# pse84 register map
Vendor: Infineon Technologies; Series: PSE84; File version: 1.0
CPU: CM33 r0p1, little endian, MPU, FPU, VTOR, 3 interrupt priority bits
Registers are 32-bit, read-write, reset 0x0 unless marked. A register's access mark holds for its fields unless they carry their own. Offsets are from the block's base; [hi:lo] are bit positions; lines under a group give offsets from that group; {n}, {i} and the like mark numbered series; <NAME> marks a mode.

## SMIF0 (part 1 of 3) — SMIF subsystem (1 SMIF cores, no bridge, 1 cache_block and 1 Q_LPI expander)
Base 0x44440000
Same registers: SMIF1 0x44480000
0x10000 CACHE_BLOCK group — Serial Memory Interface
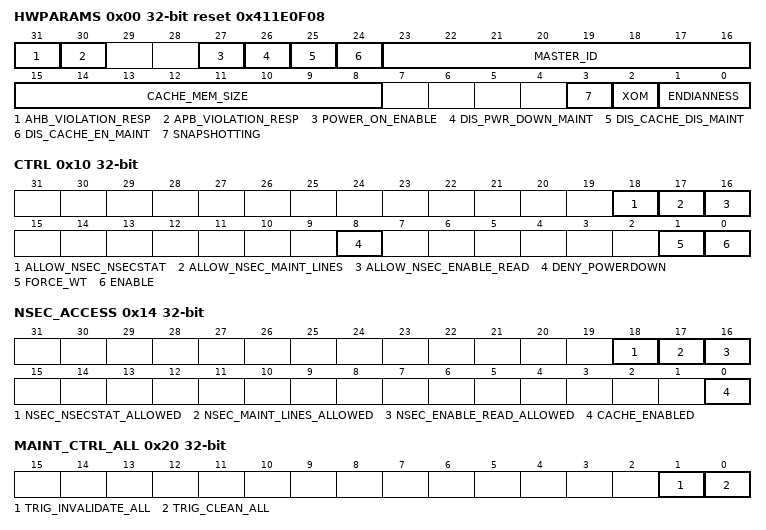
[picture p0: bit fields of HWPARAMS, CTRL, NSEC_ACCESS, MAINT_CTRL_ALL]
  0x00 HWPARAMS ro reset 0x411E0F08 — Hardware Parameter register
    [31] AHB_VIOLATION_RESP — Respond with error (1) or RAZ/WI (0) for illegal AHB operations (eg. XOM). Fixed to 0 if XOM render parameter is OFF
    [30] APB_VIOLATION_RESP — Respond with error (1) or RAZ/WI (0) for illegal APB operations. These are transfers that are any of: non-privileged, instruction, unaligned or incomplete write strobes
    [27] POWER_ON_ENABLE — Value of the input configuration port that controls whether the cache should be enabled automatically after power up
    [26] DIS_PWR_DOWN_MAINT — Value of the input configuration port that controls the function to disable automatic clean at power down
    [25] DIS_CACHE_DIS_MAINT — Value of the input configuration port that controls the function to disable automatic maintenance at disabling the cache
    [24] DIS_CACHE_EN_MAINT — Value of the input configuration port that controls the function to disable automatic maintenance at enabling the cache
    [23:16] MASTER_ID — The cache generates transactions with this ID
    [15:8] CACHE_MEM_SIZE — Cache memory size in address bits. The actual size is this value to the power of 2 (11->2KB,..,16->64KB)
    [3] SNAPSHOTTING — SNAPSHOTTING supported 1-ON, 0-OFF
    [2] XOM — XOM supported 1-ON, 0-OFF
    [1:0] ENDIANNESS — The endianness of the module 0 - LE, 1 - BE8, 2 - BE32
  0x10 CTRL — Control Register
    [18] ALLOW_NSEC_NSECSTAT — Allow non-secure to read and control non-secure statistics counter registers and receive saturation interrupt
    [17] ALLOW_NSEC_MAINT_LINES — Allow non-secure to trigger maintenance (only for lines and only non-secure views of cache lines)
    [16] ALLOW_NSEC_ENABLE_READ — Allow non-secure to see if the cache is enabled
    [8] DENY_POWERDOWN — When set, power-down LPI requests are denied. Does not affect clock LPI requests.
    [1] FORCE_WT — Force Write-Through policy
    [0] ENABLE — Enable cache (1-enabled, 0-disabled)
  0x14 NSEC_ACCESS ro — Non-secure access information
    [18] NSEC_NSECSTAT_ALLOWED — Non-secure is allowed to read and control non-secure statistics counters and receives saturation interrupt
    [17] NSEC_MAINT_LINES_ALLOWED — Non-secure is allowed to trigger maintenance (only for lines)
    [16] NSEC_ENABLE_READ_ALLOWED — Non-secure is allowed to see the cache enabled state
    [0] CACHE_ENABLED — Enable cache (1-enabled, 0-disabled). Only valid if bit NSEC_ENABLE_READ_ALLOWED is set
  0x20 MAINT_CTRL_ALL wo — Maintenance control for the entire cache
    [1] TRIG_INVALIDATE_ALL — Trigger Invalidate on all cache (can be used together with cleaning)
    [0] TRIG_CLEAN_ALL — Trigger Cleaning on all cache (can be used together with invalidate)
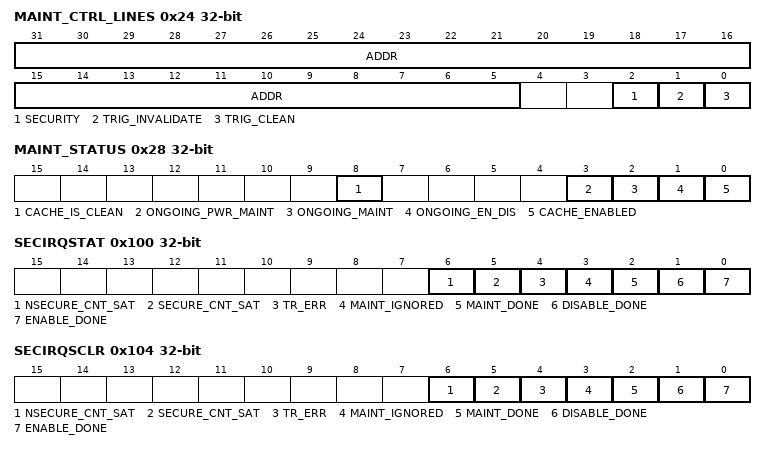
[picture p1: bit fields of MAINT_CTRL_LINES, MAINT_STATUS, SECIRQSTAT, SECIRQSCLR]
  0x24 MAINT_CTRL_LINES wo — Maintenance control for individual lines
    [31:5] ADDR — Address to look up in the cache and perform invalidate or cleaning on matching cache line. Use bits [31:5] of the address.
    [2] SECURITY — Cache maintenance is performed on the secure or non-secure view of the address. (It is possible to have both the secure and non-secure views of the same address allocated in the cache.) 0 - Secure, 1 - Non-secure; For non-secure accesses, this is ignored, and the non-secure is selected always
    [1] TRIG_INVALIDATE — Trigger Invalidate on addressed cache line
    [0] TRIG_CLEAN — Trigger Cleaning on addressed cache line
  0x28 MAINT_STATUS ro — Maintenance status for the cache
    [8] CACHE_IS_CLEAN — Reading 1 means the cache doesnt have dirty data.
    [3] ONGOING_PWR_MAINT — Reading 1 means a full cache cleaning operation is in progress triggered by a power down request.
    [2] ONGOING_MAINT — Reading 1 means a cache maintenance operation is in progress (clean and/or invalidate or enable/disable).
    [1] ONGOING_EN_DIS — Ongoing Enable or Disable. Reading 1 means the cache is in progress of being disabled or enabled and the CACHE_ENABLED bit will change when done.
    [0] CACHE_ENABLED — Cache enable status. Reading 1 means the cache is enabled, 0 the cache is disabled
  0x100 SECIRQSTAT ro — Secure Interrupt Request Status register
    [6] NSECURE_CNT_SAT — Non-secure statistics counters saturated and stopped (when ALLOW_NSEC_NSECSTAT is not set)
    [5] SECURE_CNT_SAT — Secure statistics counters saturated and stopped
    [4] TR_ERR — Secure transaction error on master side (any bus error, data type access to XOM)
    [3] MAINT_IGNORED — Secure software attempted maintenance or enable/disable of cache while such an operation was already in progress and the new request was ignored.
    [2] MAINT_DONE — Manual maintenance operation (clean and/or invalidate) started by secure software finished
    [1] DISABLE_DONE — Disable operation completed, cache is bypassed
    [0] ENABLE_DONE — Enable operation completed, cache is operational
  0x104 SECIRQSCLR wo — Secure Interrupt Status Clear register
    [6] NSECURE_CNT_SAT — Clear NSECURE_CNT_SAT interrupt
    [5] SECURE_CNT_SAT — Clear SECURE_CNT_SAT interrupt
    [4] TR_ERR — Clear secure TR_ERR Interrupt
    [3] MAINT_IGNORED — Clear secure MAINT_IGNORED interrupt
    [2] MAINT_DONE — Clear secure MAINT_DONE interrupt
    [1] DISABLE_DONE — Clear secure DISABLE_DONE interrupt
    [0] ENABLE_DONE — Clear ENABLE_DONE interrupt
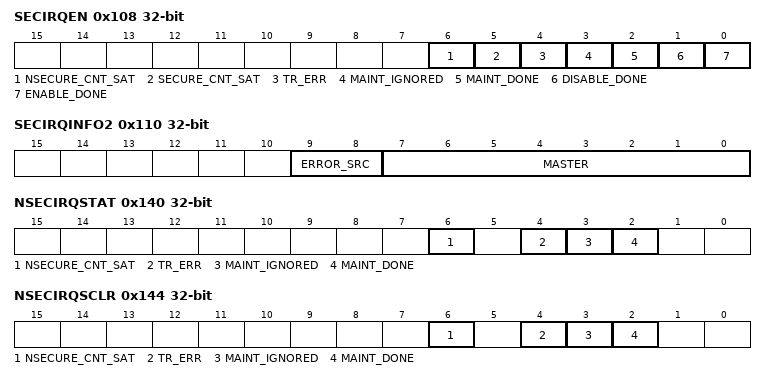
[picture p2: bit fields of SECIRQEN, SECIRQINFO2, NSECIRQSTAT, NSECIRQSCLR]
  0x108 SECIRQEN — Secure Interrupt Enable register
    [6] NSECURE_CNT_SAT — Enable NSECURE_CNT_SAT interrupt
    [5] SECURE_CNT_SAT — Enable SECURE_CNT_SAT interrupt
    [4] TR_ERR — Enable secure TR_ERR Interrupt
    [3] MAINT_IGNORED — Enable secure MAINT_IGNORED interrupt
    [2] MAINT_DONE — Enable secure MAINT_DONE interrupt
    [1] DISABLE_DONE — Enable secure DISABLE_DONE interrupt
    [0] ENABLE_DONE — Enable ENABLE_DONE interrupt
  0x10C SECIRQINFO1 ro — Secure transfer error information 1
    [31:0] ADDR — Address used by the secure transfer that caused the SECURE_TR_ERR
  0x110 SECIRQINFO2 ro — Secure transfer error information 2
    [9:8] ERROR_SRC — Origin of the secure transfer that received the bus error
    [7:0] MASTER — HMASTER ID of the secure transfer that caused the error
  0x140 NSECIRQSTAT ro — Non-secure Interrupt Request Status register
    [6] NSECURE_CNT_SAT — Non-secure statistics counters saturated and stopped (when ALLOW_NSEC_NSECSTAT is not set)
    [4] TR_ERR — Non-secure transaction error on master side.The details of the transaction are saved in the NSECIRQINFOx registers.
    [3] MAINT_IGNORED — Non-secure software attempted maintenance or enable/disable of cache while such an operation was already in progress and the new request was ignored.
    [2] MAINT_DONE — Manual maintenance operation (clean and/or invalidate) started by non-secure software finished
  0x144 NSECIRQSCLR wo — Non-secure Interrupt Status Clear register
    [6] NSECURE_CNT_SAT — Clear NSECURE_CNT_SAT interrupt
    [4] TR_ERR — Clear non-secure TR_ERR Interrupt
    [3] MAINT_IGNORED — Clear non-secure MAINT_IGNORED interrupt
    [2] MAINT_DONE — Clear non-secure MAINT_DONE interrupt
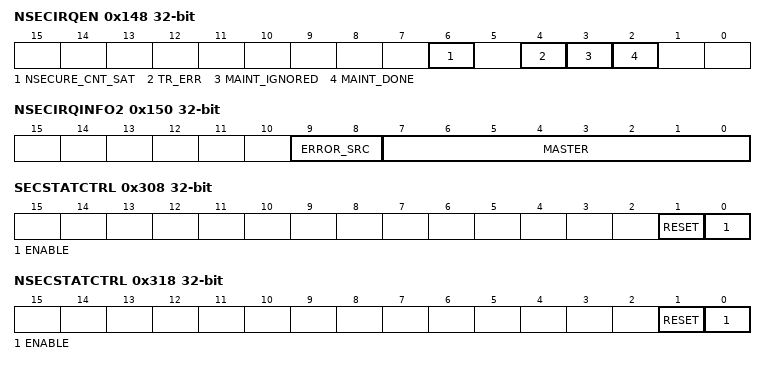
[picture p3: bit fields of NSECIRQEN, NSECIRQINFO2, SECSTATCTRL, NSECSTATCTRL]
  0x148 NSECIRQEN — Non-secure Interrupt Enable register
    [6] NSECURE_CNT_SAT — Enable NSECURE_CNT_SAT interrupt
    [4] TR_ERR — Enable non-secure TR_ERR Interrupt
    [3] MAINT_IGNORED — Enable non-secure MAINT_IGNORED interrupt
    [2] MAINT_DONE — Enable non-secure MAINT_DONE interrupt
  0x14C NSECIRQINFO1 ro — Non-secure transfer error information 1
    [31:0] ADDR — Address used by the non-secure transfer that caused NSECURE_TR_ERR
  0x150 NSECIRQINFO2 ro — Non-secure transfer error information 2
    [9:8] ERROR_SRC — Origin of the non-secure transfer that received the bus error
    [7:0] MASTER — HMASTER ID of the non-secure transfer that caused the error
  0x300 SECHIT ro — Secure transfers Hit register
    [31:0] SECHITCNT — Number of secure transfers that hit the cache
  0x304 SECMISS ro — Secure transfers Miss register
    [31:0] SECMISSCNT — Number of secure transfers that missed the cache
  0x308 SECSTATCTRL — Secure transfers statistic counters control
    [1] RESET — Reset statistics counters for secure transactions
    [0] ENABLE — Enable statistics counters for secure transactions
  0x310 NSECHIT ro — Non-secure transfers Hit register
    [31:0] NSECHITCNT — Number of non-secure transfers that hit the cache
  0x314 NSECMISS ro — Non-secure transfers Miss register
    [31:0] NSECMISSCNT — Number of non-secure transfers that missed the cache
  0x318 NSECSTATCTRL — Non-secure transfers statistic counters control
    [1] RESET — Reset statistics counters for non-secure transactions
    [0] ENABLE — Enable statistics counters for non-secure transactions
  0x600 PMSVR0 ro — Saved Value Register 0 - Secure Hit
    [31:0] SHCS — Secure hit counter snapshot
  0x604 PMSVR1 ro — Saved Value Register 1 - Secure Miss
    [31:0] SMCS — Secure miss counter snapshot
  0x608 PMSVR2 ro — Saved Value Register 2 - Non-secure Hit
    [31:0] NSHCS — Non-secure hit counter snapshot
  0x60C PMSVR3 ro — Saved Value Register 3 - Non-secure Miss
    [31:0] NSMCS — Non-secure miss counter snapshot
  0x680 PMSSSR ro reset 0x1 — PMU Snapshot Status Register
    [0] NC — No capture. Indicates whether the PMU counters have been captured
  0x6F0 PMSSCR wo — PMU Snapshot Capture Register
    [0] SS — Provides a mechanism for software to initiate a sample. Writing 1 initiates a capture immediately. Writing 0 is ignored.
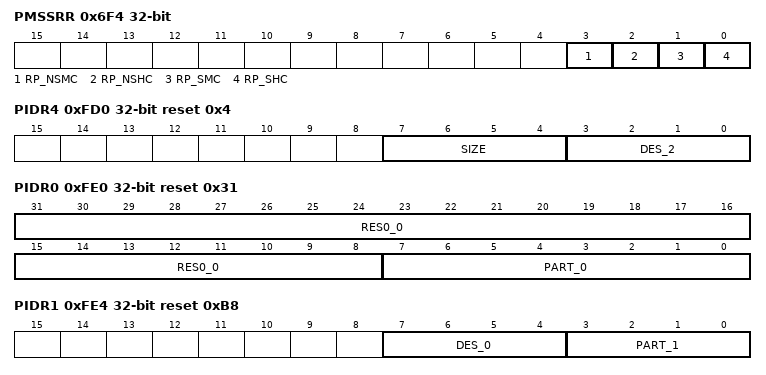
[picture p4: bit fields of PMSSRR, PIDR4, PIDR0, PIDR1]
  0x6F4 PMSSRR — PMU Snapshot Reset Register
    [3] RP_NSMC — Reset non-secure miss counter when making snapshot. Mirrors RP_NSHC as the 2 counters are grouped and should not be reset separately
    [2] RP_NSHC — Reset non-secure hit counter when making snapshot. Miss counter copies this value
    [1] RP_SMC — Reset secure miss counter when making snapshot. Mirrors RP_SHC as the 2 counters are grouped and should not be reset separately
    [0] RP_SHC — Reset secure hit counter when making snapshot. Miss counter copies this value
  0xFD0 PIDR4 ro reset 0x4 — Peripheral ID 4
    [7:4] SIZE — 4KB Count.
    [3:0] DES_2 — JEP106 Continuation Code.
  {0xFC0+4j} PIDR{j} ro (j=5..7) — Peripheral ID {j}
    [31:0] RSVD
  0xFE0 PIDR0 ro reset 0x31 — Peripheral ID 0
    [31:8] RES0_0
    [7:0] PART_0 — Part Number [7:0].
  0xFE4 PIDR1 ro reset 0xB8 — Peripheral ID 1
    [7:4] DES_0 — JEP106 Identity Code [3:0].
    [3:0] PART_1 — Part Number [11:8].
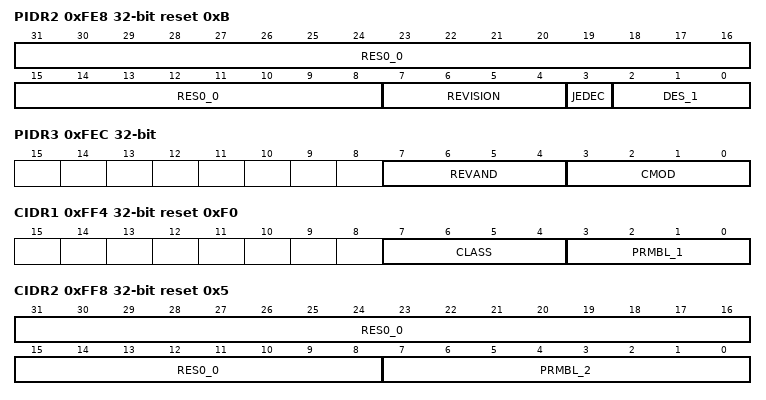
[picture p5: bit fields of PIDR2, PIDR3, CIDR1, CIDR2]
  0xFE8 PIDR2 ro reset 0xB — Peripheral ID 2
    [31:8] RES0_0
    [7:4] REVISION — Revision Code.
    [3] JEDEC
    [2:0] DES_1 — JEP106 Identity Code [6:4].
  0xFEC PIDR3 ro — Peripheral ID 3
    [7:4] REVAND — Manufacturer revision number.
    [3:0] CMOD — Customer Modified.
  0xFF0 CIDR0 ro reset 0xD — Component ID 0
    [7:0] PRMBL_0 — Preamble.
  0xFF4 CIDR1 ro reset 0xF0 — Component ID 1
    [7:4] CLASS — Component class.
    [3:0] PRMBL_1 — Preamble.
  0xFF8 CIDR2 ro reset 0x5 — Component ID 2
    [31:8] RES0_0
    [7:0] PRMBL_2 — Preamble.
  0xFFC CIDR3 ro reset 0xB1 — Component ID 3
    [7:0] PRMBL_3 — Preamble.
  0x2000 MMIO group — MMIO regs for cacheblock (anything other than cache IP related MMIO regs)
    0x00 BYPASS_WI — Bypass wrap to increment conversion logic
      [0] BYPASS_WI — 0 = Do Not Bypass wrap to increment conversion logic 1 = Bypass wrap to increment conversion logic
    0x04 MASTER_ID reset 0x1E — The cache generates transactions (linefill and eviction Write-Back) that are marked with the value specified by MASTER_ID on hmaster_m.
      [7:0] MASTER_ID — The cache generates transactions (linefill and eviction Write-Back) that are marked with the given value on hmaster_m.
    0x08 DIS_CACHE_EN_MAINT reset 0x1 — This signal turns on/off cache enable maintenance.
      [0] DIS_CACHE_EN_MAINT — The dis_cache_en_maint port determines if the AHB Cache starts the predefined cache maintenance before the cache enable command would take effect. dis_cache_en_maint = 1 The AHB Cache does not start any maintenance before applying the cache enable command. Caution If cache enable maintenance is disabled, the software must manage the AHB Cache. It must invalidate the content before cache enable if: - The cache RAMs have not been invalidated after the last power cycle. - The content is not valid anymore. Otherwise the data in the cacheable regions is corrupted. dis_cache_en_maint = 0, The AHB Cache starts invalidate all maintenance before it applies the cache enable command that it has received on the APB interface. While the cache enable maintenance is running, the AHB Cache works as if it were disabled. The traffic is not affected. When the invalidation is completed, the next NSEQ transaction on the AHB slave interface is looked up in the cache according to its transaction attributes. The status of ongoing enable or disable related maintenance can be read at MAINT_STATUS.ONGOING_EN_DIS status register bit. The effective enabled or disabled status can be read at MAINT_STATUS.CACHE_ENABLED status register bit.
    0x0C DIS_CACHE_DIS_MAINT — This signal turns on/off cache disable maintenance.
      [0] DIS_CACHE_DIS_MAINT — The dis_cache_dis_maint determines if the AHB Cache starts the predefined cache maintenance before the cache disable command would take effect. dis_cache_dis_maint = 1 The AHB Cache drains the internal buffers but does not complete any other maintenance before applying the cache disable command. It only waits for any ongoing Burst on the AHB slave interface to finish. Caution If cache disable maintenance is disabled, the software must manage the AHB Cache. If there is any dirty data in the cache RAMs, the software must clean the cache before disable. Otherwise, the main memory is not updated. dis_cache_dis_maint = 0, The AHB Cache starts clean all maintenance before it applies the cache disable command that it has received on the APB interface. While this maintenance is running, the AHB Cache stalls the AHB slave interface. After accepting the disable command, the AHB Cache stalls the AHB traffic at the next NSEQ transaction on the AHB slave interface. Then it runs a clean all maintenance process and when it is completed the disable becomes effective and the AHB slave interface is released. The status of ongoing disable related maintenance can be read at MAINT_STATUS.ONGOING_EN_DIS status register bit. The effective enabled or disabled status can be read at MAINT_STATUS.CACHE_ENABLED status register bit.
    0x10 APB_VIOLATION_RESP reset 0x1 — This signal controls if the APB interface of cache responds with an error to illegal operations on the APB interface. Illegal operations on the APB interface include Writing with no full write strobe, Accessing non-word aligned addresses, Instruction accesses, Non-privileged accesses 1 - The Cache responds with an APB error. Read data is masked with zeros and write data is ignored. 0 - The Cache sends an OK response. Read data is masked with zeros and write data is ignored.
      [0] APB_VIOLATION_RESP — This bit controls if the APB interface of cache responds with an error to illegal operations on the APB interface. Illegal operations on the APB interface include Writing with no full write strobe, Accessing non-word aligned addresses, Instruction accesses, Non-privileged accesses 1 - The AHB Cache responds with an APB error. Read data is masked with zeros and write data is ignored. 0 - The AHB Cache sends an OK response. Read data is masked with zeros and write data is ignored.
    0x14 MMIO_ACTIVE_EN reset 0x1 — SW control to put SMIF.6 in active or clock gated mode
      [0] MMIO_ACTIVE_EN — SW control to put SMIF.6 in active or clock gated mode 0 - Software writes this value to put SMIF.6 in clock gated mode w/ clocks gated 1 - Software writes this value to put SMIF.6 in active mode w/ clocks from MXSPERI restored
    0x18 POWER_ON_ENABLE — This signal configures the cache to enable the cache automatically after powerup.
      [0] POWER_ON_ENABLE — The power_on_enable port can be set so that the AHB Cache is enabled when the LPI interfaces first reach QRUN state after reset. The cache enable bit is combinatorially driven from this bit. With a default of 0, cache comes up disabled upon cold start. Before enabling the cache, the SW should set this bit to 1 (if it intends to have the cache come-up enabled after power-down/power-up sequence). The expected behaviour here is that this bit is retained during cache power down and when cache is subsequently powered down and back up, this bit would drive the cache enable bit to 1, thereby automatically enabling the cache. If the SW wants to use the cache contents upon return from deep sleep, it should make sure to have set dis_cache_en_maint set to 1 prior to going into deep sleep. Setting dis_cache_en_maint to 1 has an effect of preventing a cache from doing a force invalidate of cache lines prior to enable. power_on_enable = 1 The cache is enabled automatically after powerup. This signal is affected by the dis_cache_en_maint. power_on_enable = 0 The cache waits for software to enable the cache through the APB programming interface.
    0x1C MMIO_CACHE_RET_EN reset 0x1 — Controls if cache SRAMs are retained during DPSLP
      [0] MMIO_CACHE_RET_EN — mmio_cache_ret_en = 1 The cache SRAM array retains contents even when cache controller is powered down. mmio_cache_ret_en = 0 The cache SRAM array does not retain its contents even when cache controller is powered down. NOTE This bit controls the retention only in DPSLP mode. In DPSLP_RAM and DPSLP_OFF modes cache is never retained regarless of the setting of this bit.
    0x20 DIS_PWR_DOWN_MAINT — This signal turns on/off powerdown maintenance.
      [0] DIS_PWR_DOWN_MAINT — The dis_pwr_down_maint port determines if the AHB Cache starts the predefined cache maintenance process before accepting a powerdown request. dis_pwr_down_maint = 1 If there is no deny condition, the AHB Cache merges any data from its internal buffers into the cache RAMs and accepts the power quiescence request immediately. dis_pwr_down_maint = 0 The AHB Cache checks the cache clean status whenever a power quiescence request is received through the power Q-Channel interface. If the cache status is clean and otherwise idle, then it accepts the quiescence request. If the cache status is dirty but otherwise idle, it starts a clean all maintenance process. The AHB Cache delays the response and only denies the request if a dirty line is actually found in the cache memory during the maintenance operation. During powerdown maintenance, any AHB activity that would cause a power quiescence request to be denied (except for the maintenance driven activity) results in the maintenance being aborted. Any subsequent quiescence request is denied while the maintenance is in progress. The status of the powerdown maintenance can be monitored - On the pwr_maintenance output port. This port is driven high only while this process is running. - By reading the MAINT_STATUS.ONGOING_PWR_MAINT status register bit.
    0x24 REGION0_BASE — Region 0 Attributes - register 0; Region attributes shall be changed exclusively while the SMIF is disabled, and the XIP interfaces are idle
      [26:12] ADDR — Determines the base address of a region 0 within a SMIF external memory address space The region 0 is hit when REGION0_LIMIT.ENABLE bit is set to 1 and transfer address is inside the range defined by REGION0_BASE.ADDR and REGION0_LIMIT.ADDR: REGION0_BASE.ADDR <= address[26:12] <= REGION0_LIMIT.ADDR Regions are not allowed to overlap; it is SW responsibility to set BASE and LIMIT address values for enabled regions in a way that there is no overlap. HW is not having any protection and will not generate any notification/interrupt in case of wrong configuration.
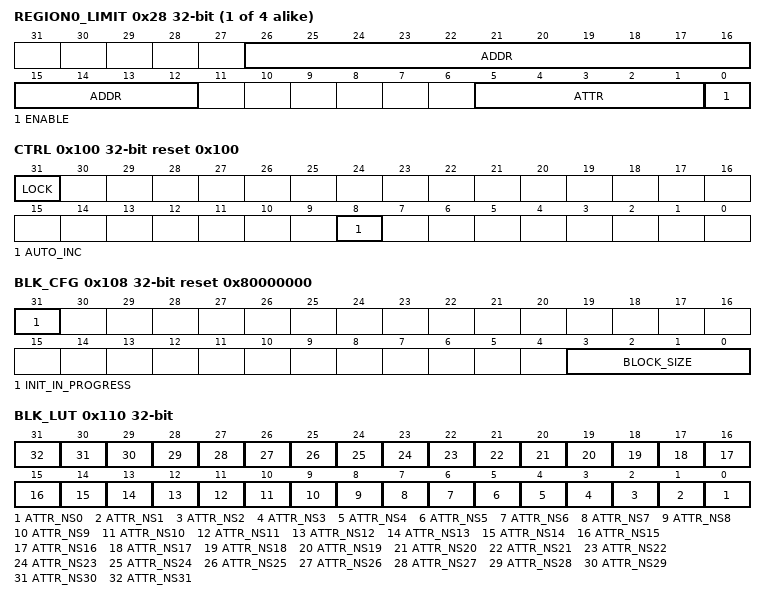
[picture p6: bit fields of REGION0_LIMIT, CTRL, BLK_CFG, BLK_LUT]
    {0x28+8k} REGION{k}_LIMIT (k=0..3) — Region {k} Attributes - register 1; Region attributes shall be changed exclusively while the SMIF is disabled, and the XIP interfaces are idle
      [26:12] ADDR — Determines the end address of a region {k} within a SMIF external memory address space Regions are not allowed to overlap; it is SW responsibility to set BASE and LIMIT address values for enabled regions in a way that there is no overlap. HW is not having any protection and will not generate any notification/interrupt in case of wrong configuration
      [5:1] ATTR — This field defines transaction attributes for the region {k} and indicates how the transaction should be handled within a Cache Block: [5] R: Read Allocate [4] W: Write Allocate [3] L: Lookup [2] M: Modifiable [1] B: Bufferable The following ATTR values are supported: 5'b00000 - Non-Cacheable, Non-Bufferable (reset value) - nCnB 5'b00001 - Non-Cacheable, Bufferable - nCB 5'b01110 - Cacheable, Write Through, Write Allocate - WTWA 5'b10110 - Cacheable, Write Through, Read Allocate - WTRA 5'b11110 - Cacheable, Write Through, Read & Write Allocate - WTRWA 5'b01111 - Cacheable, Write Back , Write Allocate - WBWA 5'b10111 - Cacheable, Write Back , Read Allocate - WBRA 5'b11111 - Cacheable, Write Back , Read & Write Allocate - WBRWA If region is enabled and transaction address is hitting the predefined region address range, corresponding ATTR field is used to overwrite transaction HPROT bits
      [0] ENABLE — Region {k} Enable By default, all regions are disabled (all transfers are interpreted as non-cacheable)
    {0x24+8k} REGION{k}_BASE (k=1..3) — Region {k} Attributes - register 0; Region attributes shall be changed exclusively while the SMIF is disabled, and the XIP interfaces are idle
      [26:12] ADDR — Determines the base address of a region {k} within a SMIF external memory address space The region {k} is hit when REGION{k}_LIMIT.ENABLE bit is set to 1 and transfer address is inside the range defined by REGION{k}_BASE.ADDR and REGION{k}_LIMIT.ADDR: REGION{k}_BASE.ADDR <= address[26:12] <= REGION{k}_LIMIT.ADDR Regions are not allowed to overlap; it is SW responsibility to set BASE and LIMIT address values for enabled regions in a way that there is no overlap. HW is not having any protection and will not generate any notification/interrupt in case of wrong configuration
  0x4000 CACHEBLK_AHB group — SMIF Cacheblock MPC
    0x00 MPC group — MPC Memory Protection Controller registers
      0x00 CFG — Config register with error response, RegionID PPC_MPC_MAIN is the security owner PC. The error response configuration is located in CFG.RESPONSE, only one such configuration exists applying to all protection contexts in the system.
        [4] RESPONSE — Response Configuration for Security and PC violations 0: Read-Zero Write Ignore (RAZ/WI) 1: Bus Error
      0x100 CTRL reset 0x100 — Control register with lock bit and auto-increment only (Separate CTRL for each PC depends on access_pc)
        [31] LOCK — Security lockdown for this protection context. Software can set this bit but not clear it once set. When set, write operations to BLK_LUT are not possible from this protection context. Setting LOCK also blocks writes to CTRL itself (for that PC copy). All writes are ignored.
        [8] AUTO_INC — Auto-increment BLK_IDX by 1 for this protection context as a side effect of each read/write access to BLK_LUT
      0x104 BLK_MAX ro — Max value of block-based index register
        [31:0] VALUE — Maximum value of block-based index register. The number and size blocks in an MPC is design time configurable and for embedded memories defaults to covering the entire memory using 4kB blocks; See product datasheet for details on protection of external memories.
      0x108 BLK_CFG ro reset 0x80000000 — Block size & initialization in progress
        [31] INIT_IN_PROGRESS — During initialization INIT_IN_PROGRESS is '1' and MMIO register accesses to BLK_LUT is blocked (BLK_IDX increment is also ignored). The block attributes are retained in DeepSleep (and obviously Active) power mode. Initialization is only required from a power mode in which the block attributes are not retained. E.g., initialization is required for a cold boot (after a Power-on-Reset). HW initializes the block attributes: the NS attributes are set to '0' (secure), the R attributes are set to '1' (read access allowed) and the W attributes are set to '1' (write access allowed). During initialization, the MPC supports memory accesses (memory accesses are NOT blocked) with the initialization block attribute values as mentioned above. This e.g. allows MPC initialization to proceed in parallel with boot program memory accesses (as opposed to serializing the two), improving device boot time.
        [3:0] BLOCK_SIZE — Block size of individually protected blocks (0: 32B, 1: 64B, ... up to 15: 1MB) Block size= (1<<(BLOCK_SIZE+5)) The number and size blocks in an MPC is design time configurable and for embedded memories defaults to covering the entire memory using 4kB blocks; see product datasheet for details on protection of external memories.
      0x10C BLK_IDX — Index of 32-block group accessed through BLK_LUT (Separate IDX for each PC depending on access_pc)
        [31:0] VALUE — Index value for accessing block-based lookup table using BLK_LUT. Programming out of LUT range is an user error and it loops back to '0' once overflow occurs.
      0x110 BLK_LUT — NS status for 32 blocks at BLK_IDX with PC=<access_pc>
        [n] ATTR_NS{n} (n=0..31) — NS bit for block {n} based on BLK_IDX
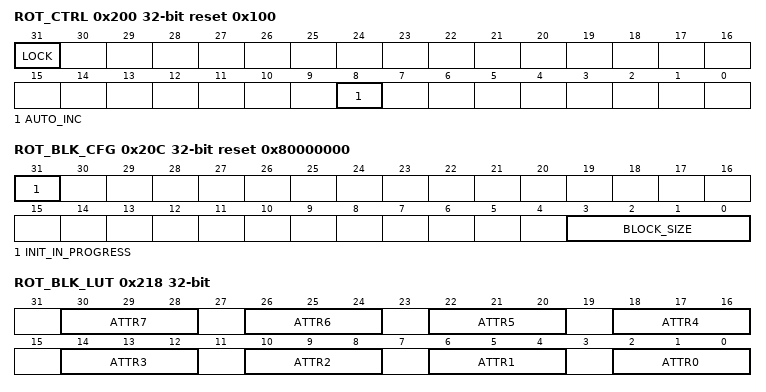
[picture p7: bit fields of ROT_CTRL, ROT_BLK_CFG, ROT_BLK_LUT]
      0x200 ROT_CTRL reset 0x100 — Control register with lock bit and auto-increment only
        [31] LOCK — Security lockdown for the root-of-trust configuration registers. Software can set this bit but not clear it once set. When set, write operations to ROT_BLK_LUT are not possible. Write is ignored.
        [8] AUTO_INC — Auto-increment BLK_IDX by 1 for each read/write of ROT_BLK_LUT
      0x208 ROT_BLK_MAX ro — Max value of block-based index register for ROT
        [31:0] VALUE — Maximum value of block-based index register. The number and size blocks in an MPC is design time configurable and for embedded memories defaults to covering the entire memory using 4kB blocks; see product datasheet for details on protection of external memories.
      0x20C ROT_BLK_CFG ro reset 0x80000000 — Same as BLK_CFG
        [31] INIT_IN_PROGRESS — During initialization INIT_IN_PROGRESS is '1' and MMIO register accesses to ROT_BLK_LUT is RAZWI. The block attributes are retained in DeepSleep (and obviously Active) power mode. Initialization is only required from a power mode in which the block attributes are not retained. E.g., initialization is required for a cold boot (after a Power-on-Reset). HW initializes the block attributes: the NS attributes are set to '0' (secure), the R attributes are set to '1' (read access allowed) and the W attributes are set to '1' (write access allowed). During initialization, the MPC supports memory accesses (memory accesses are NOT blocked) with the initialization block attribute values as mentioned above. This e.g. allows MPC initialization to proceed in parallel with boot program memory accesses (as opposed to serializing the two), improving device boot time.
        [3:0] BLOCK_SIZE — Block size of individually protected blocks (0: 32B, 1: 64B, ...up to 15:1MB) Block size= (1<<(BLOCK_SIZE+5)) The number and size blocks in an MPC is design time configurable and for embedded memories defaults to covering the entire memory using 4kB blocks; see product datasheet for details on protection of external memories.
      0x210 ROT_BLK_IDX — Index of 8-block group accessed through ROT_BLK_LUT_*
        [31:0] VALUE — Index value for accessing block-based lookup table using ROT_BLK_LUT. Programming out of LUT range is an user error and it loops back to '0' once overflow occurs.
      0x214 ROT_BLK_PC — Protection context of 8-block group accesses through ROT_BLK_LUT
        [3:0] PC — Specify PC values for ROT_BLK_IDX and ROT_BLK_LUT
      0x218 ROT_BLK_LUT — (R,W,NS) bits for 8 blocks at ROT_BLK_IDX for PC=ROT_BKL_PC
        [4n+2:4n] ATTR{n} (n=0..7) — W/R/NS bits for block {n} indicated by ROT_BLK_IDX for ROT_BLK_PC PC
